VERSION ""

NS_ :

BS_:

BU_:

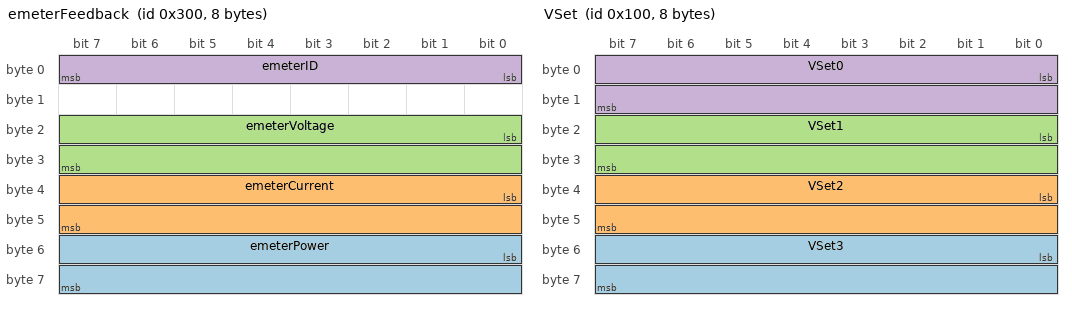
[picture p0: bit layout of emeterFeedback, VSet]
BO_ 768 emeterFeedback: 8 Vector__XXX
 SG_ emeterPower : 48|16@1+ (1,0) [0|0] "" Vector__XXX
 SG_ emeterCurrent : 32|16@1- (1,0) [0|0] "" Vector__XXX
 SG_ emeterVoltage : 16|16@1+ (1,0) [0|0] "" Vector__XXX
 SG_ emeterID : 0|8@1+ (1,0) [0|0] "" Vector__XXX

BO_ 512 RelaySet: 1 Vector__XXX
 SG_ RelaySettings : 0|4@1+ (1,0) [0|0] "" Vector__XXX

BO_ 256 VSet: 8 Vector__XXX
 SG_ VSet3 : 48|16@1+ (1,0) [0|0] "" Vector__XXX
 SG_ VSet2 : 32|16@1+ (1,0) [0|0] "" Vector__XXX
 SG_ VSet1 : 16|16@1+ (1,0) [0|0] "" Vector__XXX
 SG_ VSet0 : 0|16@1+ (1,0) [0|0] "" Vector__XXX

BA_DEF_  "BusType" STRING ;
BA_DEF_DEF_  "BusType" "CAN";
